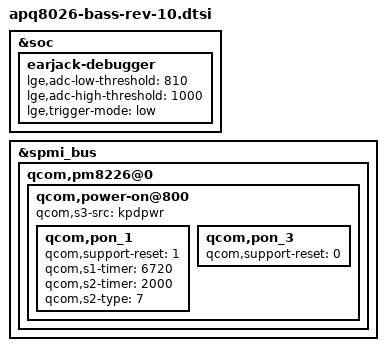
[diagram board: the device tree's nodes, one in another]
/* Copyright (c) 2015, LGE Inc. All rights reserved.
 *
 * This program is free software; you can redistribute it and/or modify
 * it under the terms of the GNU General Public License version 2 and
 * only version 2 as published by the Free Software Foundation.
 *
 * This program is distributed in the hope that it will be useful,
 * but WITHOUT ANY WARRANTY; without even the implied warranty of
 * MERCHANTABILITY or FITNESS FOR A PARTICULAR PURPOSE.  See the
 * GNU General Public License for more details.
 */

#include "apq8026-bass.dtsi"

&soc {
	earjack-debugger {
		status = "ok";
		lge,adc-low-threshold = <810>;
		lge,adc-high-threshold = <1000>;
		lge,trigger-mode = "low";
	};
};

&spmi_bus {
	qcom,pm8226@0 {
		qcom,power-on@800 {
			qcom,s3-src = "kpdpwr";
			qcom,pon_1 {
				qcom,support-reset = <1>;
				qcom,s1-timer = <6720>;
				qcom,s2-timer = <2000>;
				qcom,s2-type = <7>;
			};
			qcom,pon_3 {
				qcom,support-reset = <0>;
			};
		};
	};
};
